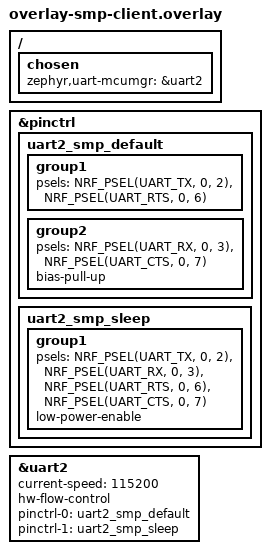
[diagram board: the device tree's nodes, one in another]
/*
 * Copyright (c) 2026 Nordic Semiconductor ASA
 *
 * SPDX-License-Identifier: LicenseRef-Nordic-5-Clause
 */

/ {
	chosen {
		/* SMP transport on uart2 (SERIAL2, free because the board overlay
		 * disables i2c2). uart1 stays as the VCOM1 console/log UART, so the
		 * app's sm_log never suspends the SMP link.
		 *
		 * Pins are the free Arduino-header GPIOs D2/D3/D6/D7
		 * (P0.02/03/06/07). The earlier P0.28/29/30/31 choice collided with
		 * VCOM1's own console pins (P0.28/29) and the on-board TWI/I2C2 bus
		 * (P0.30/31, with pull-ups), which corrupted the SMP framing.
		 */
		zephyr,uart-mcumgr = &uart2;
	};
};

&pinctrl {
	uart2_smp_default: uart2_smp_default {
		group1 {
			psels = <NRF_PSEL(UART_TX, 0, 2)>,
				<NRF_PSEL(UART_RTS, 0, 6)>;
		};

		group2 {
			psels = <NRF_PSEL(UART_RX, 0, 3)>,
				<NRF_PSEL(UART_CTS, 0, 7)>;
			bias-pull-up;
		};
	};

	uart2_smp_sleep: uart2_smp_sleep {
		group1 {
			psels = <NRF_PSEL(UART_TX, 0, 2)>,
				<NRF_PSEL(UART_RX, 0, 3)>,
				<NRF_PSEL(UART_RTS, 0, 6)>,
				<NRF_PSEL(UART_CTS, 0, 7)>;
			low-power-enable;
		};
	};
};

&uart2 {
	status = "okay";
	current-speed = <115200>;
	hw-flow-control;
	pinctrl-0 = <&uart2_smp_default>;
	pinctrl-1 = <&uart2_smp_sleep>;
	pinctrl-names = "default", "sleep";
};
